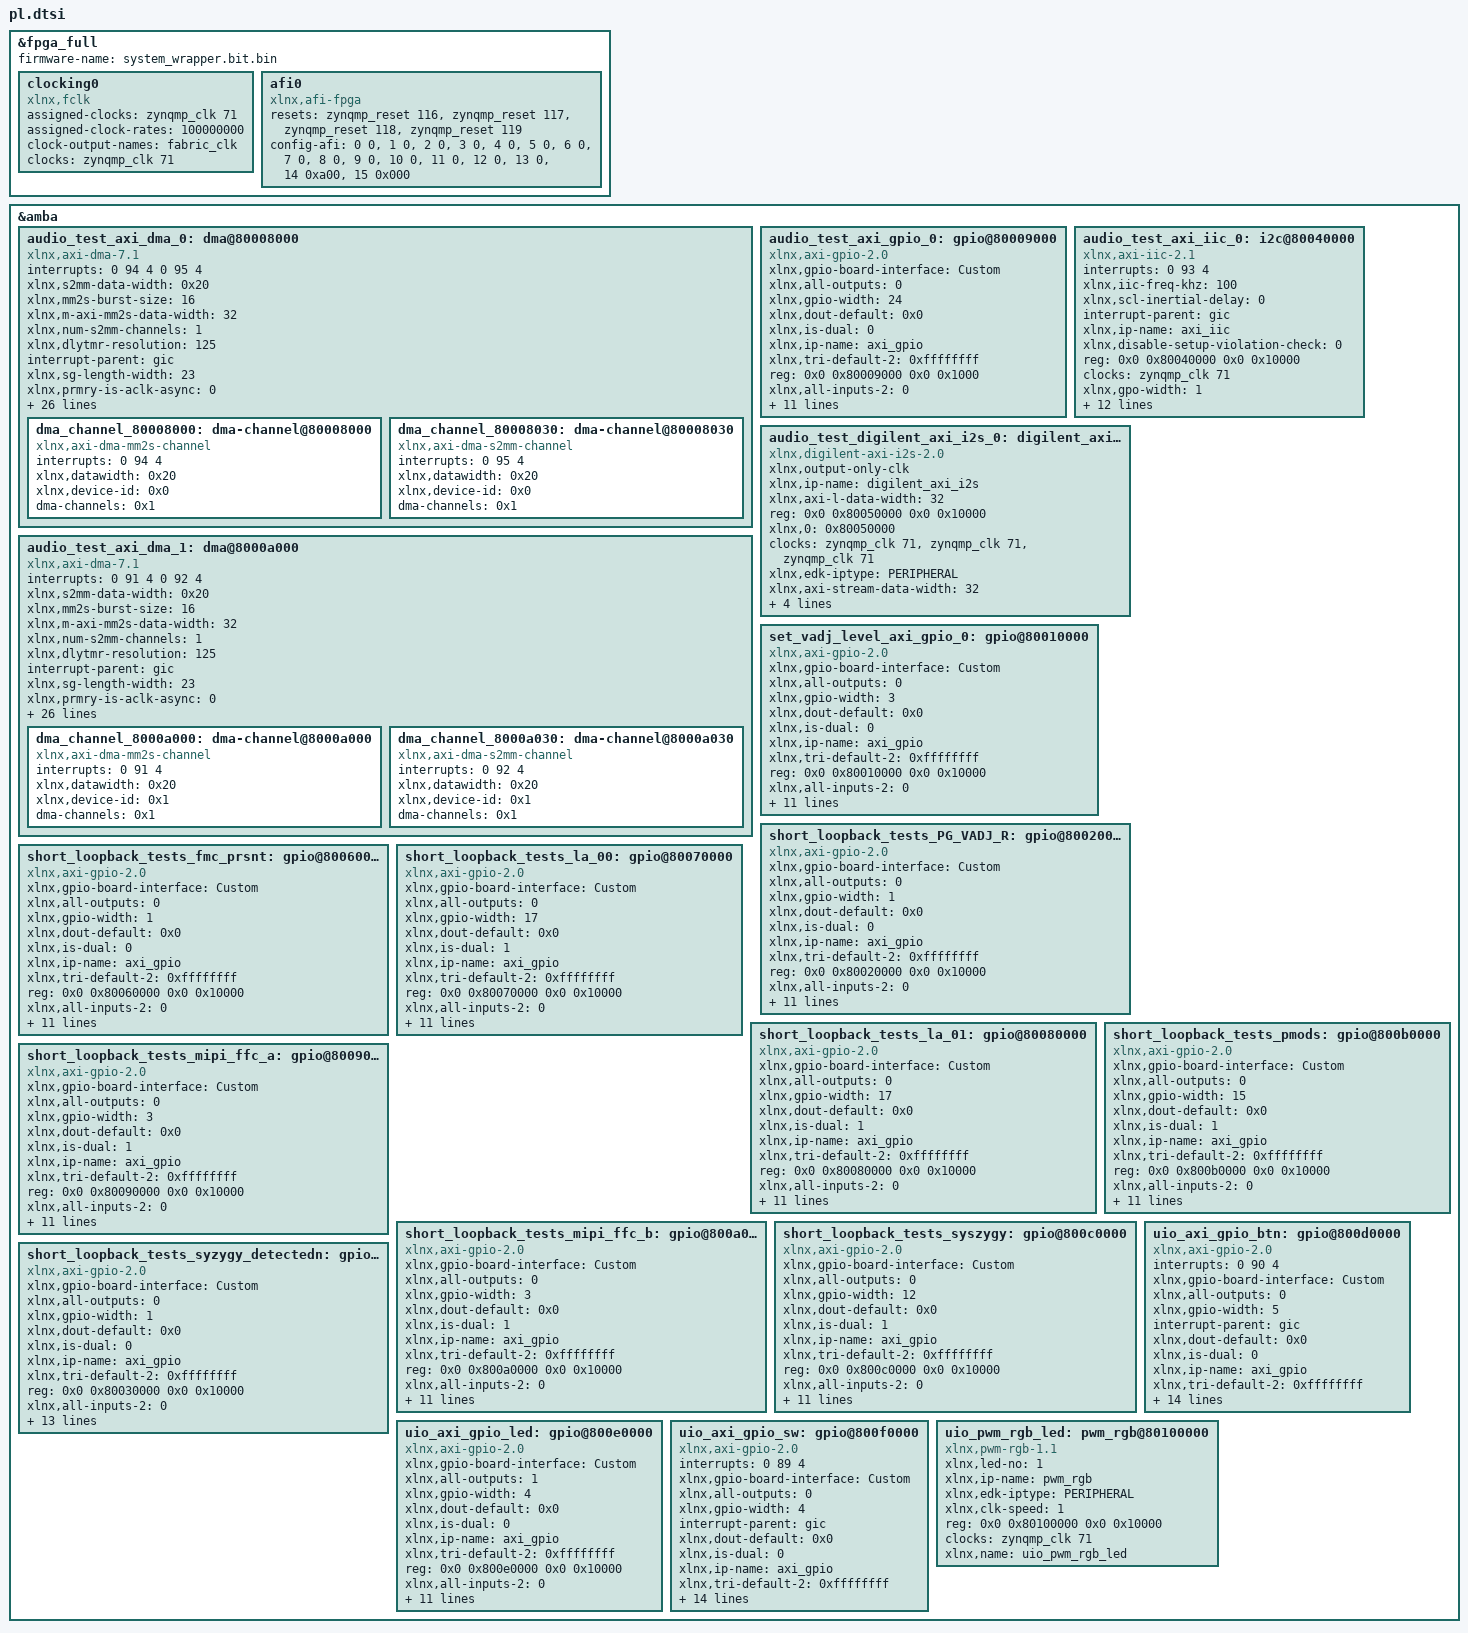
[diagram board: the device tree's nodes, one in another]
/dts-v1/;
/plugin/;
&fpga_full {
	firmware-name = "system_wrapper.bit.bin";
	clocking0: clocking0 {
		compatible = "xlnx,fclk";
		assigned-clocks = <&zynqmp_clk 71>;
		assigned-clock-rates = <100000000>;
		#clock-cells = <0>;
		clock-output-names = "fabric_clk";
		clocks = <&zynqmp_clk 71>;
	};
	afi0: afi0 {
		compatible = "xlnx,afi-fpga";
		resets = <&zynqmp_reset 116>, <&zynqmp_reset 117>, <&zynqmp_reset 118>, <&zynqmp_reset 119>;
		config-afi = < 0 0>, <1 0>, <2 0>, <3 0>, <4 0>, <5 0>, <6 0>, <7 0>, <8 0>, <9 0>, <10 0>, <11 0>, <12 0>, <13 0>, <14 0xa00>, <15 0x000>;
	};
};

&amba {
	audio_test_axi_dma_0: dma@80008000 {
		interrupts = < 0 94 4 0 95 4 >;
		compatible = "xlnx,axi-dma-7.1" , "xlnx,axi-dma-1.00.a";
		xlnx,s2mm-data-width = <0x20>;
		xlnx,mm2s-burst-size = <16>;
		xlnx,m-axi-mm2s-data-width = <32>;
		xlnx,num-s2mm-channels = <1>;
		xlnx,dlytmr-resolution = <125>;
		interrupt-parent = <&gic>;
		xlnx,sg-length-width = <23>;
		xlnx,prmry-is-aclk-async = <0>;
		xlnx,include-s2mm-sf = <1>;
		#dma-cells = <1>;
		xlnx,ip-name = "axi_dma";
		xlnx,single-interface = <0>;
		xlnx,sg-include-stscntrl-strm = <0>;
		xlnx,include-s2mm-dre = <0>;
		reg = <0x0 0x80008000 0x0 0x1000>;
		xlnx,addr-width = <32>;
		xlnx,include-s2mm = <1>;
		clocks = <&zynqmp_clk 71>, <&zynqmp_clk 71>, <&zynqmp_clk 71>;
		xlnx,s-axis-s2mm-tdata-width = <32>;
		xlnx,micro-dma = <0>;
		xlnx,increase-throughput = <0>;
		xlnx,mm2s-data-width = <0x20>;
		xlnx,addrwidth = <0x20>;
		xlnx,sg-use-stsapp-length = <0>;
		xlnx,m-axis-mm2s-tdata-width = <32>;
		xlnx,edk-iptype = "PERIPHERAL";
		xlnx,s2mm-burst-size = <16>;
		xlnx,m-axi-s2mm-data-width = <32>;
		xlnx,num-mm2s-channels = <1>;
		xlnx,enable-multi-channel = <0>;
		xlnx,include-mm2s-sf = <1>;
		clock-names = "m_axi_mm2s_aclk" , "m_axi_s2mm_aclk" , "s_axi_lite_aclk";
		interrupt-names = "mm2s_introut" , "s2mm_introut";
		xlnx,include-mm2s = <1>;
		xlnx,include-mm2s-dre = <0>;
		xlnx,name = "audio_test_axi_dma_0";
		dma_channel_80008000: dma-channel@80008000 {
			interrupts = <0 94 4>;
			xlnx,datawidth = <0x20>;
			xlnx,device-id = <0x0>;
			compatible = "xlnx,axi-dma-mm2s-channel";
			dma-channels = <0x1>;
		};
		dma_channel_80008030: dma-channel@80008030 {
			interrupts = <0 95 4>;
			xlnx,datawidth = <0x20>;
			xlnx,device-id = <0x0>;
			compatible = "xlnx,axi-dma-s2mm-channel";
			dma-channels = <0x1>;
		};
	};
	audio_test_axi_dma_1: dma@8000a000 {
		interrupts = < 0 91 4 0 92 4 >;
		compatible = "xlnx,axi-dma-7.1" , "xlnx,axi-dma-1.00.a";
		xlnx,s2mm-data-width = <0x20>;
		xlnx,mm2s-burst-size = <16>;
		xlnx,m-axi-mm2s-data-width = <32>;
		xlnx,num-s2mm-channels = <1>;
		xlnx,dlytmr-resolution = <125>;
		interrupt-parent = <&gic>;
		xlnx,sg-length-width = <23>;
		xlnx,prmry-is-aclk-async = <0>;
		xlnx,include-s2mm-sf = <1>;
		#dma-cells = <1>;
		xlnx,ip-name = "axi_dma";
		xlnx,single-interface = <0>;
		xlnx,sg-include-stscntrl-strm = <0>;
		xlnx,include-s2mm-dre = <0>;
		reg = <0x0 0x8000a000 0x0 0x1000>;
		xlnx,addr-width = <32>;
		xlnx,include-s2mm = <1>;
		clocks = <&zynqmp_clk 71>, <&zynqmp_clk 71>, <&zynqmp_clk 71>;
		xlnx,s-axis-s2mm-tdata-width = <32>;
		xlnx,micro-dma = <0>;
		xlnx,increase-throughput = <0>;
		xlnx,mm2s-data-width = <0x20>;
		xlnx,addrwidth = <0x20>;
		xlnx,sg-use-stsapp-length = <0>;
		xlnx,m-axis-mm2s-tdata-width = <32>;
		xlnx,edk-iptype = "PERIPHERAL";
		xlnx,s2mm-burst-size = <16>;
		xlnx,m-axi-s2mm-data-width = <32>;
		xlnx,num-mm2s-channels = <1>;
		xlnx,enable-multi-channel = <0>;
		xlnx,include-mm2s-sf = <1>;
		clock-names = "m_axi_mm2s_aclk" , "m_axi_s2mm_aclk" , "s_axi_lite_aclk";
		interrupt-names = "mm2s_introut" , "s2mm_introut";
		xlnx,include-mm2s = <1>;
		xlnx,include-mm2s-dre = <0>;
		xlnx,name = "audio_test_axi_dma_1";
		dma_channel_8000a000: dma-channel@8000a000 {
			interrupts = <0 91 4>;
			xlnx,datawidth = <0x20>;
			xlnx,device-id = <0x1>;
			compatible = "xlnx,axi-dma-mm2s-channel";
			dma-channels = <0x1>;
		};
		dma_channel_8000a030: dma-channel@8000a030 {
			interrupts = <0 92 4>;
			xlnx,datawidth = <0x20>;
			xlnx,device-id = <0x1>;
			compatible = "xlnx,axi-dma-s2mm-channel";
			dma-channels = <0x1>;
		};
	};
	audio_test_axi_gpio_0: gpio@80009000 {
		xlnx,gpio-board-interface = "Custom";
		compatible = "xlnx,axi-gpio-2.0" , "xlnx,xps-gpio-1.00.a";
		xlnx,all-outputs = <0>;
		#gpio-cells = <2>;
		xlnx,gpio-width = <24>;
		xlnx,dout-default = <0x0>;
		xlnx,is-dual = <0>;
		xlnx,ip-name = "axi_gpio";
		xlnx,tri-default-2 = <0xffffffff>;
		reg = <0x0 0x80009000 0x0 0x1000>;
		xlnx,all-inputs-2 = <0>;
		clocks = <&zynqmp_clk 71>;
		xlnx,all-outputs-2 = <0>;
		gpio-controller;
		xlnx,interrupt-present = <0>;
		xlnx,gpio2-board-interface = "Custom";
		xlnx,edk-iptype = "PERIPHERAL";
		xlnx,dout-default-2 = <0x0>;
		xlnx,gpio2-width = <32>;
		clock-names = "s_axi_aclk";
		xlnx,tri-default = <0xffffffff>;
		xlnx,name = "audio_test_axi_gpio_0";
		xlnx,all-inputs = <0>;
	};
	audio_test_axi_iic_0: i2c@80040000 {
		interrupts = < 0 93 4 >;
		xlnx,iic-freq-khz = <100>;
		compatible = "xlnx,axi-iic-2.1" , "xlnx,xps-iic-2.00.a";
		xlnx,scl-inertial-delay = <0>;
		interrupt-parent = <&gic>;
		xlnx,ip-name = "axi_iic";
		xlnx,disable-setup-violation-check = <0>;
		reg = <0x0 0x80040000 0x0 0x10000>;
		clocks = <&zynqmp_clk 71>;
		xlnx,gpo-width = <1>;
		xlnx,edk-iptype = "PERIPHERAL";
		xlnx,static-timing-reg-width = <0>;
		xlnx,sda-level = <1>;
		clock-names = "s_axi_aclk";
		xlnx,ten-bit-adr = <0>;
		xlnx,default-value = <0x0>;
		interrupt-names = "iic2intc_irpt";
		xlnx,iic-board-interface = "Custom";
		xlnx,timing-reg-width = <32>;
		xlnx,iic-freq = <100000>;
		xlnx,smbus-pmbus-host = <0>;
		xlnx,name = "audio_test_axi_iic_0";
		xlnx,axi-aclk-freq-mhz = <100>;
		xlnx,sda-inertial-delay = <0>;
	};
	audio_test_digilent_axi_i2s_0: digilent_axi_i2s@80050000 {
		compatible = "xlnx,digilent-axi-i2s-2.0";
		xlnx,output-only-clk;
		xlnx,ip-name = "digilent_axi_i2s";
		xlnx,axi-l-data-width = <32>;
		reg = <0x0 0x80050000 0x0 0x10000>;
		xlnx,0 = <0x80050000>;
		clocks = <&zynqmp_clk 71>, <&zynqmp_clk 71>, <&zynqmp_clk 71>;
		xlnx,edk-iptype = "PERIPHERAL";
		clock-names = "AXI_L_aclk" , "M_AXIS_S2MM_ACLK" , "S_AXIS_MM2S_ACLK";
		xlnx,axi-stream-data-width = <32>;
		xlnx,data-width = <24>;
		xlnx,axi-l-addr-width = <6>;
		xlnx,enable-stream;
		xlnx,name = "audio_test_digilent_axi_i2s_0";
	};
	set_vadj_level_axi_gpio_0: gpio@80010000 {
		xlnx,gpio-board-interface = "Custom";
		compatible = "xlnx,axi-gpio-2.0" , "xlnx,xps-gpio-1.00.a";
		xlnx,all-outputs = <0>;
		#gpio-cells = <2>;
		xlnx,gpio-width = <3>;
		xlnx,dout-default = <0x0>;
		xlnx,is-dual = <0>;
		xlnx,ip-name = "axi_gpio";
		xlnx,tri-default-2 = <0xffffffff>;
		reg = <0x0 0x80010000 0x0 0x10000>;
		xlnx,all-inputs-2 = <0>;
		clocks = <&zynqmp_clk 71>;
		xlnx,all-outputs-2 = <0>;
		gpio-controller;
		xlnx,interrupt-present = <0>;
		xlnx,gpio2-board-interface = "Custom";
		xlnx,edk-iptype = "PERIPHERAL";
		xlnx,dout-default-2 = <0x0>;
		xlnx,gpio2-width = <32>;
		clock-names = "s_axi_aclk";
		xlnx,tri-default = <0xffffffff>;
		xlnx,name = "set_vadj_level_axi_gpio_0";
		xlnx,all-inputs = <0>;
	};
	short_loopback_tests_PG_VADJ_R: gpio@80020000 {
		xlnx,gpio-board-interface = "Custom";
		compatible = "xlnx,axi-gpio-2.0" , "xlnx,xps-gpio-1.00.a";
		xlnx,all-outputs = <0>;
		#gpio-cells = <2>;
		xlnx,gpio-width = <1>;
		xlnx,dout-default = <0x0>;
		xlnx,is-dual = <0>;
		xlnx,ip-name = "axi_gpio";
		xlnx,tri-default-2 = <0xffffffff>;
		reg = <0x0 0x80020000 0x0 0x10000>;
		xlnx,all-inputs-2 = <0>;
		clocks = <&zynqmp_clk 71>;
		xlnx,all-outputs-2 = <0>;
		gpio-controller;
		xlnx,interrupt-present = <0>;
		xlnx,gpio2-board-interface = "Custom";
		xlnx,edk-iptype = "PERIPHERAL";
		xlnx,dout-default-2 = <0x0>;
		xlnx,gpio2-width = <32>;
		clock-names = "s_axi_aclk";
		xlnx,tri-default = <0xffffffff>;
		xlnx,name = "short_loopback_tests_PG_VADJ_R";
		xlnx,all-inputs = <1>;
	};
	short_loopback_tests_fmc_prsnt: gpio@80060000 {
		xlnx,gpio-board-interface = "Custom";
		compatible = "xlnx,axi-gpio-2.0" , "xlnx,xps-gpio-1.00.a";
		xlnx,all-outputs = <0>;
		#gpio-cells = <2>;
		xlnx,gpio-width = <1>;
		xlnx,dout-default = <0x0>;
		xlnx,is-dual = <0>;
		xlnx,ip-name = "axi_gpio";
		xlnx,tri-default-2 = <0xffffffff>;
		reg = <0x0 0x80060000 0x0 0x10000>;
		xlnx,all-inputs-2 = <0>;
		clocks = <&zynqmp_clk 71>;
		xlnx,all-outputs-2 = <0>;
		gpio-controller;
		xlnx,interrupt-present = <0>;
		xlnx,gpio2-board-interface = "Custom";
		xlnx,edk-iptype = "PERIPHERAL";
		xlnx,dout-default-2 = <0x0>;
		xlnx,gpio2-width = <32>;
		clock-names = "s_axi_aclk";
		xlnx,tri-default = <0xffffffff>;
		xlnx,name = "short_loopback_tests_fmc_prsnt";
		xlnx,all-inputs = <1>;
	};
	short_loopback_tests_la_00: gpio@80070000 {
		xlnx,gpio-board-interface = "Custom";
		compatible = "xlnx,axi-gpio-2.0" , "xlnx,xps-gpio-1.00.a";
		xlnx,all-outputs = <0>;
		#gpio-cells = <2>;
		xlnx,gpio-width = <17>;
		xlnx,dout-default = <0x0>;
		xlnx,is-dual = <1>;
		xlnx,ip-name = "axi_gpio";
		xlnx,tri-default-2 = <0xffffffff>;
		reg = <0x0 0x80070000 0x0 0x10000>;
		xlnx,all-inputs-2 = <0>;
		clocks = <&zynqmp_clk 71>;
		xlnx,all-outputs-2 = <0>;
		gpio-controller;
		xlnx,interrupt-present = <0>;
		xlnx,gpio2-board-interface = "Custom";
		xlnx,edk-iptype = "PERIPHERAL";
		xlnx,dout-default-2 = <0x0>;
		xlnx,gpio2-width = <17>;
		clock-names = "s_axi_aclk";
		xlnx,tri-default = <0xffffffff>;
		xlnx,name = "short_loopback_tests_la_00";
		xlnx,all-inputs = <0>;
	};
	short_loopback_tests_la_01: gpio@80080000 {
		xlnx,gpio-board-interface = "Custom";
		compatible = "xlnx,axi-gpio-2.0" , "xlnx,xps-gpio-1.00.a";
		xlnx,all-outputs = <0>;
		#gpio-cells = <2>;
		xlnx,gpio-width = <17>;
		xlnx,dout-default = <0x0>;
		xlnx,is-dual = <1>;
		xlnx,ip-name = "axi_gpio";
		xlnx,tri-default-2 = <0xffffffff>;
		reg = <0x0 0x80080000 0x0 0x10000>;
		xlnx,all-inputs-2 = <0>;
		clocks = <&zynqmp_clk 71>;
		xlnx,all-outputs-2 = <0>;
		gpio-controller;
		xlnx,interrupt-present = <0>;
		xlnx,gpio2-board-interface = "Custom";
		xlnx,edk-iptype = "PERIPHERAL";
		xlnx,dout-default-2 = <0x0>;
		xlnx,gpio2-width = <17>;
		clock-names = "s_axi_aclk";
		xlnx,tri-default = <0xffffffff>;
		xlnx,name = "short_loopback_tests_la_01";
		xlnx,all-inputs = <0>;
	};
	short_loopback_tests_mipi_ffc_a: gpio@80090000 {
		xlnx,gpio-board-interface = "Custom";
		compatible = "xlnx,axi-gpio-2.0" , "xlnx,xps-gpio-1.00.a";
		xlnx,all-outputs = <0>;
		#gpio-cells = <2>;
		xlnx,gpio-width = <3>;
		xlnx,dout-default = <0x0>;
		xlnx,is-dual = <1>;
		xlnx,ip-name = "axi_gpio";
		xlnx,tri-default-2 = <0xffffffff>;
		reg = <0x0 0x80090000 0x0 0x10000>;
		xlnx,all-inputs-2 = <0>;
		clocks = <&zynqmp_clk 71>;
		xlnx,all-outputs-2 = <0>;
		gpio-controller;
		xlnx,interrupt-present = <0>;
		xlnx,gpio2-board-interface = "Custom";
		xlnx,edk-iptype = "PERIPHERAL";
		xlnx,dout-default-2 = <0x0>;
		xlnx,gpio2-width = <3>;
		clock-names = "s_axi_aclk";
		xlnx,tri-default = <0xffffffff>;
		xlnx,name = "short_loopback_tests_mipi_ffc_a";
		xlnx,all-inputs = <0>;
	};
	short_loopback_tests_mipi_ffc_b: gpio@800a0000 {
		xlnx,gpio-board-interface = "Custom";
		compatible = "xlnx,axi-gpio-2.0" , "xlnx,xps-gpio-1.00.a";
		xlnx,all-outputs = <0>;
		#gpio-cells = <2>;
		xlnx,gpio-width = <3>;
		xlnx,dout-default = <0x0>;
		xlnx,is-dual = <1>;
		xlnx,ip-name = "axi_gpio";
		xlnx,tri-default-2 = <0xffffffff>;
		reg = <0x0 0x800a0000 0x0 0x10000>;
		xlnx,all-inputs-2 = <0>;
		clocks = <&zynqmp_clk 71>;
		xlnx,all-outputs-2 = <0>;
		gpio-controller;
		xlnx,interrupt-present = <0>;
		xlnx,gpio2-board-interface = "Custom";
		xlnx,edk-iptype = "PERIPHERAL";
		xlnx,dout-default-2 = <0x0>;
		xlnx,gpio2-width = <3>;
		clock-names = "s_axi_aclk";
		xlnx,tri-default = <0xffffffff>;
		xlnx,name = "short_loopback_tests_mipi_ffc_b";
		xlnx,all-inputs = <0>;
	};
	short_loopback_tests_pmods: gpio@800b0000 {
		xlnx,gpio-board-interface = "Custom";
		compatible = "xlnx,axi-gpio-2.0" , "xlnx,xps-gpio-1.00.a";
		xlnx,all-outputs = <0>;
		#gpio-cells = <2>;
		xlnx,gpio-width = <15>;
		xlnx,dout-default = <0x0>;
		xlnx,is-dual = <1>;
		xlnx,ip-name = "axi_gpio";
		xlnx,tri-default-2 = <0xffffffff>;
		reg = <0x0 0x800b0000 0x0 0x10000>;
		xlnx,all-inputs-2 = <0>;
		clocks = <&zynqmp_clk 71>;
		xlnx,all-outputs-2 = <0>;
		gpio-controller;
		xlnx,interrupt-present = <0>;
		xlnx,gpio2-board-interface = "Custom";
		xlnx,edk-iptype = "PERIPHERAL";
		xlnx,dout-default-2 = <0x0>;
		xlnx,gpio2-width = <15>;
		clock-names = "s_axi_aclk";
		xlnx,tri-default = <0xffffffff>;
		xlnx,name = "short_loopback_tests_pmods";
		xlnx,all-inputs = <0>;
	};
	short_loopback_tests_syszygy: gpio@800c0000 {
		xlnx,gpio-board-interface = "Custom";
		compatible = "xlnx,axi-gpio-2.0" , "xlnx,xps-gpio-1.00.a";
		xlnx,all-outputs = <0>;
		#gpio-cells = <2>;
		xlnx,gpio-width = <12>;
		xlnx,dout-default = <0x0>;
		xlnx,is-dual = <1>;
		xlnx,ip-name = "axi_gpio";
		xlnx,tri-default-2 = <0xffffffff>;
		reg = <0x0 0x800c0000 0x0 0x10000>;
		xlnx,all-inputs-2 = <0>;
		clocks = <&zynqmp_clk 71>;
		xlnx,all-outputs-2 = <0>;
		gpio-controller;
		xlnx,interrupt-present = <0>;
		xlnx,gpio2-board-interface = "Custom";
		xlnx,edk-iptype = "PERIPHERAL";
		xlnx,dout-default-2 = <0x0>;
		xlnx,gpio2-width = <12>;
		clock-names = "s_axi_aclk";
		xlnx,tri-default = <0xffffffff>;
		xlnx,name = "short_loopback_tests_syszygy";
		xlnx,all-inputs = <0>;
	};
	short_loopback_tests_syzygy_detectedn: gpio@80030000 {
		xlnx,gpio-board-interface = "Custom";
		compatible = "xlnx,axi-gpio-2.0" , "xlnx,xps-gpio-1.00.a";
		xlnx,all-outputs = <0>;
		#gpio-cells = <2>;
		xlnx,gpio-width = <1>;
		xlnx,dout-default = <0x0>;
		xlnx,is-dual = <0>;
		xlnx,ip-name = "axi_gpio";
		xlnx,tri-default-2 = <0xffffffff>;
		reg = <0x0 0x80030000 0x0 0x10000>;
		xlnx,all-inputs-2 = <0>;
		clocks = <&zynqmp_clk 71>;
		xlnx,all-outputs-2 = <0>;
		gpio-controller;
		xlnx,interrupt-present = <0>;
		xlnx,gpio2-board-interface = "Custom";
		xlnx,edk-iptype = "PERIPHERAL";
		xlnx,dout-default-2 = <0x0>;
		xlnx,gpio2-width = <32>;
		clock-names = "s_axi_aclk";
		xlnx,use-board-flow;
		xlnx,tri-default = <0xffffffff>;
		xlnx,name = "short_loopback_tests_syzygy_detectedn";
		xlnx,all-inputs = <1>;
	};
	uio_axi_gpio_btn: gpio@800d0000 {
		#interrupt-cells = <2>;
		interrupts = < 0 90 4 >;
		xlnx,gpio-board-interface = "Custom";
		compatible = "xlnx,axi-gpio-2.0" , "xlnx,xps-gpio-1.00.a";
		xlnx,all-outputs = <0>;
		#gpio-cells = <2>;
		xlnx,gpio-width = <5>;
		interrupt-parent = <&gic>;
		xlnx,dout-default = <0x0>;
		xlnx,is-dual = <0>;
		xlnx,ip-name = "axi_gpio";
		xlnx,tri-default-2 = <0xffffffff>;
		reg = <0x0 0x800d0000 0x0 0x10000>;
		xlnx,all-inputs-2 = <0>;
		clocks = <&zynqmp_clk 71>;
		xlnx,all-outputs-2 = <0>;
		gpio-controller;
		xlnx,interrupt-present = <1>;
		xlnx,gpio2-board-interface = "Custom";
		xlnx,edk-iptype = "PERIPHERAL";
		xlnx,dout-default-2 = <0x0>;
		xlnx,gpio2-width = <32>;
		clock-names = "s_axi_aclk";
		interrupt-controller;
		interrupt-names = "ip2intc_irpt";
		xlnx,tri-default = <0xffffffff>;
		xlnx,name = "uio_axi_gpio_btn";
		xlnx,all-inputs = <1>;
	};
	uio_axi_gpio_led: gpio@800e0000 {
		xlnx,gpio-board-interface = "Custom";
		compatible = "xlnx,axi-gpio-2.0" , "xlnx,xps-gpio-1.00.a";
		xlnx,all-outputs = <1>;
		#gpio-cells = <2>;
		xlnx,gpio-width = <4>;
		xlnx,dout-default = <0x0>;
		xlnx,is-dual = <0>;
		xlnx,ip-name = "axi_gpio";
		xlnx,tri-default-2 = <0xffffffff>;
		reg = <0x0 0x800e0000 0x0 0x10000>;
		xlnx,all-inputs-2 = <0>;
		clocks = <&zynqmp_clk 71>;
		xlnx,all-outputs-2 = <0>;
		gpio-controller;
		xlnx,interrupt-present = <0>;
		xlnx,gpio2-board-interface = "Custom";
		xlnx,edk-iptype = "PERIPHERAL";
		xlnx,dout-default-2 = <0x0>;
		xlnx,gpio2-width = <32>;
		clock-names = "s_axi_aclk";
		xlnx,tri-default = <0xffffffff>;
		xlnx,name = "uio_axi_gpio_led";
		xlnx,all-inputs = <0>;
	};
	uio_axi_gpio_sw: gpio@800f0000 {
		#interrupt-cells = <2>;
		interrupts = < 0 89 4 >;
		xlnx,gpio-board-interface = "Custom";
		compatible = "xlnx,axi-gpio-2.0" , "xlnx,xps-gpio-1.00.a";
		xlnx,all-outputs = <0>;
		#gpio-cells = <2>;
		xlnx,gpio-width = <4>;
		interrupt-parent = <&gic>;
		xlnx,dout-default = <0x0>;
		xlnx,is-dual = <0>;
		xlnx,ip-name = "axi_gpio";
		xlnx,tri-default-2 = <0xffffffff>;
		reg = <0x0 0x800f0000 0x0 0x10000>;
		xlnx,all-inputs-2 = <0>;
		clocks = <&zynqmp_clk 71>;
		xlnx,all-outputs-2 = <0>;
		gpio-controller;
		xlnx,interrupt-present = <1>;
		xlnx,gpio2-board-interface = "Custom";
		xlnx,edk-iptype = "PERIPHERAL";
		xlnx,dout-default-2 = <0x0>;
		xlnx,gpio2-width = <32>;
		clock-names = "s_axi_aclk";
		interrupt-controller;
		interrupt-names = "ip2intc_irpt";
		xlnx,tri-default = <0xffffffff>;
		xlnx,name = "uio_axi_gpio_sw";
		xlnx,all-inputs = <1>;
	};
	uio_pwm_rgb_led: pwm_rgb@80100000 {
		compatible = "xlnx,pwm-rgb-1.1";
		clock-names = "s_axi_aclk";
		xlnx,led-no = <1>;
		xlnx,ip-name = "pwm_rgb";
		xlnx,edk-iptype = "PERIPHERAL";
		xlnx,clk-speed = <1>;
		reg = <0x0 0x80100000 0x0 0x10000>;
		clocks = <&zynqmp_clk 71>;
		xlnx,name = "uio_pwm_rgb_led";
	};
};
